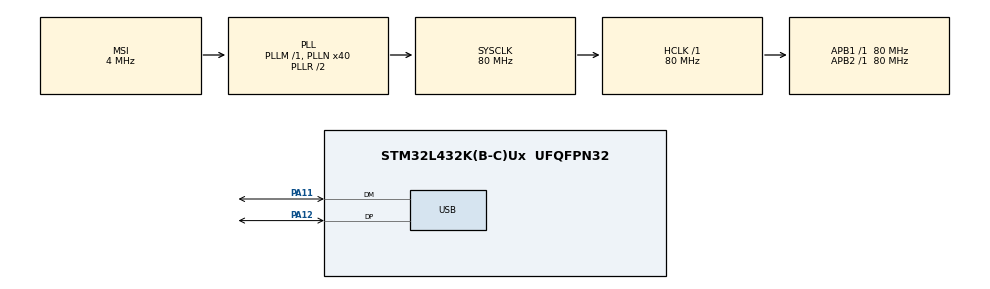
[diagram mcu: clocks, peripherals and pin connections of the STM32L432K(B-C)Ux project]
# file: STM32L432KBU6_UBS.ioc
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Mcu.Family=STM32L4
Mcu.Name=STM32L432K(B-C)Ux
Mcu.Package=UFQFPN32
NVIC.PriorityGroup=NVIC_PRIORITYGROUP_4
NVIC.USB_IRQn=true\:0\:0\:false\:false\:true\:false\:true\:true
PA11.Mode=Device
PA11.Signal=USB_DM
PA12.Mode=Device
PA12.Signal=USB_DP
PA13\ (JTMS-SWDIO).Mode=Serial_Wire
PA13\ (JTMS-SWDIO).Signal=SYS_JTMS-SWDIO
PA14\ (JTCK-SWCLK).Mode=Serial_Wire
PA14\ (JTCK-SWCLK).Signal=SYS_JTCK-SWCLK
ProjectManager.HeapSize=0x200
ProjectManager.StackSize=0x400
ProjectManager.TargetToolchain=Makefile
RCC.ADCFreq_Value=48000000
RCC.AHBFreq_Value=80000000
RCC.APB1Freq_Value=80000000
RCC.APB1TimFreq_Value=80000000
RCC.APB2Freq_Value=80000000
RCC.APB2TimFreq_Value=80000000
RCC.CortexFreq_Value=80000000
RCC.HCLKFreq_Value=80000000
RCC.HSE_VALUE=8000000
RCC.HSI48_VALUE=48000000
RCC.HSI_VALUE=16000000
RCC.LSE_VALUE=32768
RCC.MSI_VALUE=4000000
RCC.PLLN=40
RCC.PLLSAI1N=24
RCC.SYSCLKFreq_VALUE=80000000
RCC.SYSCLKSource=RCC_SYSCLKSOURCE_PLLCLK
RCC.USBFreq_Value=48000000
RCC.VCOOutputFreq_Value=160000000
USB_DEVICE.CLASS_NAME_FS=CDC
USB_DEVICE.VirtualMode=Cdc
USB_DEVICE.VirtualModeFS=Cdc_FS
VP_USB_DEVICE_VS_USB_DEVICE_CDC_FS.Mode=CDC_FS
board=custom

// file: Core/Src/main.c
/* USER CODE BEGIN Header */
/**
  ******************************************************************************
  * @file           : main.c
  * @brief          : Main program body
  ******************************************************************************
  * @attention
  *
  * Copyright (c) 2024 STMicroelectronics.
  * All rights reserved.
  *
  * This software is licensed under terms that can be found in the LICENSE file
  * in the root directory of this software component.
  * If no LICENSE file comes with this software, it is provided AS-IS.
  *
  ******************************************************************************
  */
/* USER CODE END Header */
#include "main.h"
#include "usb_device.h"

/* USER CODE BEGIN Includes */
#include "usbd_cdc_if.h"
#include "string.h"
/* USER CODE END Includes */

void SystemClock_Config(void);
static void MX_GPIO_Init(void);

/* USER CODE BEGIN 0 */
char *data = "Hello testing USB\n";
/* USER CODE END 0 */

int main(void)
{

  /* MCU Configuration--------------------------------------------------------*/

  /* Reset of all peripherals, Initializes the Flash interface and the Systick. */
  HAL_Init();

  /* Configure the system clock */
  SystemClock_Config();

  /* Initialize all configured peripherals */
  MX_GPIO_Init();
  MX_USB_DEVICE_Init();

  /* Infinite loop */
  /* USER CODE BEGIN WHILE */
  while (1)
  {

    CDC_Transmit_FS((uint8_t *) data, strlen(data));
    HAL_Delay(1000);
    /* USER CODE END WHILE */

  }
}

void SystemClock_Config(void)
{
  RCC_OscInitTypeDef RCC_OscInitStruct = {0};
  RCC_ClkInitTypeDef RCC_ClkInitStruct = {0};

  /** Configure the main internal regulator output voltage
  */
  if (HAL_PWREx_ControlVoltageScaling(PWR_REGULATOR_VOLTAGE_SCALE1) != HAL_OK)
  {
    Error_Handler();
  }

  /** Initializes the RCC Oscillators according to the specified parameters
  * in the RCC_OscInitTypeDef structure.
  */
  RCC_OscInitStruct.OscillatorType = RCC_OSCILLATORTYPE_MSI;
  RCC_OscInitStruct.MSIState = RCC_MSI_ON;
  RCC_OscInitStruct.MSICalibrationValue = 0;
  RCC_OscInitStruct.MSIClockRange = RCC_MSIRANGE_6;
  RCC_OscInitStruct.PLL.PLLState = RCC_PLL_ON;
  RCC_OscInitStruct.PLL.PLLSource = RCC_PLLSOURCE_MSI;
  RCC_OscInitStruct.PLL.PLLM = 1;
  RCC_OscInitStruct.PLL.PLLN = 40;
  RCC_OscInitStruct.PLL.PLLP = RCC_PLLP_DIV7;
  RCC_OscInitStruct.PLL.PLLQ = RCC_PLLQ_DIV2;
  RCC_OscInitStruct.PLL.PLLR = RCC_PLLR_DIV2;
  if (HAL_RCC_OscConfig(&RCC_OscInitStruct) != HAL_OK)
  {
    Error_Handler();
  }

  /** Initializes the CPU, AHB and APB buses clocks
  */
  RCC_ClkInitStruct.ClockType = RCC_CLOCKTYPE_HCLK|RCC_CLOCKTYPE_SYSCLK
                              |RCC_CLOCKTYPE_PCLK1|RCC_CLOCKTYPE_PCLK2;
  RCC_ClkInitStruct.SYSCLKSource = RCC_SYSCLKSOURCE_PLLCLK;
  RCC_ClkInitStruct.AHBCLKDivider = RCC_SYSCLK_DIV1;
  RCC_ClkInitStruct.APB1CLKDivider = RCC_HCLK_DIV1;
  RCC_ClkInitStruct.APB2CLKDivider = RCC_HCLK_DIV1;

  if (HAL_RCC_ClockConfig(&RCC_ClkInitStruct, FLASH_LATENCY_4) != HAL_OK)
  {
    Error_Handler();
  }
}

static void MX_GPIO_Init(void)
{

  /* GPIO Ports Clock Enable */
  __HAL_RCC_GPIOA_CLK_ENABLE();

}

void Error_Handler(void)
{
  __disable_irq();
  while (1)
  {
  }
}
